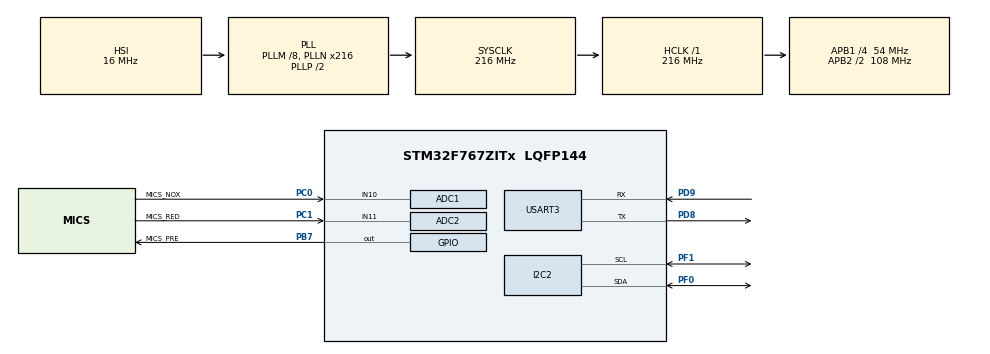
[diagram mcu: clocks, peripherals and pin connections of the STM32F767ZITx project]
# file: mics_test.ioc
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ADC1.Channel-0\#ChannelRegularConversion=ADC_CHANNEL_10
ADC1.NbrOfConversionFlag=1
ADC1.Rank-0\#ChannelRegularConversion=1
ADC1.SamplingTime-0\#ChannelRegularConversion=ADC_SAMPLETIME_3CYCLES
ADC1.master=1
ADC2.Channel-0\#ChannelRegularConversion=ADC_CHANNEL_11
ADC2.NbrOfConversionFlag=1
ADC2.Rank-0\#ChannelRegularConversion=1
ADC2.SamplingTime-0\#ChannelRegularConversion=ADC_SAMPLETIME_3CYCLES
I2C2.Timing=0x20404768
Mcu.Family=STM32F7
Mcu.Name=STM32F767ZITx
Mcu.Package=LQFP144
NVIC.PriorityGroup=NVIC_PRIORITYGROUP_4
PB7.GPIO_Label=MICS_PRE
PB7.Signal=GPIO_Output
PC0.GPIO_Label=MICS_NOX
PC0.Signal=ADCx_IN10
PC1.GPIO_Label=MICS_RED
PC1.Signal=ADCx_IN11
PD8.Mode=Asynchronous
PD8.Signal=USART3_TX
PD9.Mode=Asynchronous
PD9.Signal=USART3_RX
PF0.Mode=I2C
PF0.Signal=I2C2_SDA
PF1.Mode=I2C
PF1.Signal=I2C2_SCL
ProjectManager.HeapSize=0x200
ProjectManager.StackSize=0x400
ProjectManager.TargetToolchain=MDK-ARM V5
RCC.48MHZClocksFreq_Value=24000000
RCC.AHBFreq_Value=216000000
RCC.APB1CLKDivider=RCC_HCLK_DIV4
RCC.APB1Freq_Value=54000000
RCC.APB1TimFreq_Value=108000000
RCC.APB2CLKDivider=RCC_HCLK_DIV2
RCC.APB2Freq_Value=108000000
RCC.APB2TimFreq_Value=216000000
RCC.CortexFreq_Value=216000000
RCC.HCLKFreq_Value=216000000
RCC.HSE_VALUE=16000000
RCC.HSI_VALUE=16000000
RCC.LSE_VALUE=32768
RCC.PLLM=8
RCC.PLLMUL=RCC_PLL_MUL9
RCC.PLLN=216
RCC.PRESCALERUSB=RCC_USBCLKSOURCE_PLL_DIV1_5
RCC.SYSCLKFreq_VALUE=216000000
RCC.SYSCLKSource=RCC_SYSCLKSOURCE_PLLCLK
RCC.SYSCLKSourceVirtual=RCC_SYSCLKSOURCE_PLLCLK
RCC.USBFreq_Value=216000000
RCC.VCOOutputFreq_Value=432000000
SH.ADCx_IN10.0=ADC1_IN10,IN10
SH.ADCx_IN11.0=ADC2_IN11,IN11
USART3.VirtualMode-Asynchronous=VM_ASYNC
board=NUCLEO-F767ZI

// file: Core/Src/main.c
/* USER CODE BEGIN Header */
/**
  ******************************************************************************
  * @file           : main.c
  * @brief          : Main program body
  ******************************************************************************
  * @attention
  *
  * <h2><center>&copy; Copyright (c) 2019 STMicroelectronics.
  * All rights reserved.</center></h2>
  *
  * This software component is licensed by ST under BSD 3-Clause license,
  * the "License"; You may not use this file except in compliance with the
  * License. You may obtain a copy of the License at:
  *                        opensource.org/licenses/BSD-3-Clause
  *
  ******************************************************************************
  */
/* USER CODE END Header */

#include "main.h"
#include "adc.h"
#include "i2c.h"
#include "usart.h"
#include "gpio.h"

/* USER CODE BEGIN Includes */
#include "gas.h"
#include "environment.h"
#include "stdio.h"
#include "stdlib.h"
/* USER CODE END Includes */

void SystemClock_Config(void);

int main(void)
{

  /* MCU Configuration--------------------------------------------------------*/

  /* Reset of all peripherals, Initializes the Flash interface and the Systick. */
  HAL_Init();

  /* Configure the system clock */
  SystemClock_Config();

  /* Initialize all configured peripherals */
  MX_GPIO_Init();
  MX_ADC1_Init();
  MX_ADC2_Init();
  MX_USART3_UART_Init();
  MX_I2C2_Init();
  /* USER CODE BEGIN 2 */

	gas_init();
	environment_init();

  /* USER CODE END 2 */

  /* Infinite loop */
  /* USER CODE BEGIN WHILE */
  while (1)
  {
		HAL_Delay(1000);
		printf("NO2: %uppb,  CO: %uppb,  CO2: %uppb, TVOC: %uppb,  T: %.1f,  RH: %.1f \r\n",
			readNO2(), readCO(), readCO2(), readTVOC(), readT(), readRH());

    /* USER CODE END WHILE */

  }
}

void SystemClock_Config(void)
{
  RCC_OscInitTypeDef RCC_OscInitStruct = {0};
  RCC_ClkInitTypeDef RCC_ClkInitStruct = {0};
  RCC_PeriphCLKInitTypeDef PeriphClkInitStruct = {0};

  /** Configure the main internal regulator output voltage
  */
  __HAL_RCC_PWR_CLK_ENABLE();
  __HAL_PWR_VOLTAGESCALING_CONFIG(PWR_REGULATOR_VOLTAGE_SCALE1);
  /** Initializes the CPU, AHB and APB busses clocks
  */
  RCC_OscInitStruct.OscillatorType = RCC_OSCILLATORTYPE_HSI;
  RCC_OscInitStruct.HSIState = RCC_HSI_ON;
  RCC_OscInitStruct.HSICalibrationValue = RCC_HSICALIBRATION_DEFAULT;
  RCC_OscInitStruct.PLL.PLLState = RCC_PLL_ON;
  RCC_OscInitStruct.PLL.PLLSource = RCC_PLLSOURCE_HSI;
  RCC_OscInitStruct.PLL.PLLM = 8;
  RCC_OscInitStruct.PLL.PLLN = 216;
  RCC_OscInitStruct.PLL.PLLP = RCC_PLLP_DIV2;
  RCC_OscInitStruct.PLL.PLLQ = 2;
  if (HAL_RCC_OscConfig(&RCC_OscInitStruct) != HAL_OK)
  {
    Error_Handler();
  }
  /** Activate the Over-Drive mode
  */
  if (HAL_PWREx_EnableOverDrive() != HAL_OK)
  {
    Error_Handler();
  }
  /** Initializes the CPU, AHB and APB busses clocks
  */
  RCC_ClkInitStruct.ClockType = RCC_CLOCKTYPE_HCLK|RCC_CLOCKTYPE_SYSCLK
                              |RCC_CLOCKTYPE_PCLK1|RCC_CLOCKTYPE_PCLK2;
  RCC_ClkInitStruct.SYSCLKSource = RCC_SYSCLKSOURCE_PLLCLK;
  RCC_ClkInitStruct.AHBCLKDivider = RCC_SYSCLK_DIV1;
  RCC_ClkInitStruct.APB1CLKDivider = RCC_HCLK_DIV4;
  RCC_ClkInitStruct.APB2CLKDivider = RCC_HCLK_DIV2;

  if (HAL_RCC_ClockConfig(&RCC_ClkInitStruct, FLASH_LATENCY_7) != HAL_OK)
  {
    Error_Handler();
  }
  PeriphClkInitStruct.PeriphClockSelection = RCC_PERIPHCLK_USART3|RCC_PERIPHCLK_I2C2;
  PeriphClkInitStruct.Usart3ClockSelection = RCC_USART3CLKSOURCE_PCLK1;
  PeriphClkInitStruct.I2c2ClockSelection = RCC_I2C2CLKSOURCE_PCLK1;
  if (HAL_RCCEx_PeriphCLKConfig(&PeriphClkInitStruct) != HAL_OK)
  {
    Error_Handler();
  }
}

void Error_Handler(void)
{
}

/************************ (C) COPYRIGHT STMicroelectronics *****END OF FILE****/
